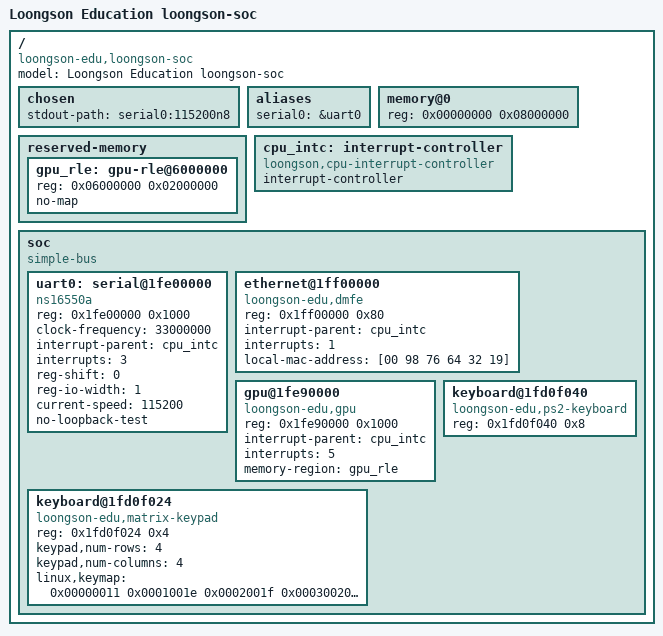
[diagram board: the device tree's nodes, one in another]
// SPDX-License-Identifier: GPL-2.0
/dts-v1/;

/ {
	model = "Loongson Education loongson-soc";
	compatible = "loongson-edu,loongson-soc";
	#address-cells = <1>;
	#size-cells = <1>;

	chosen {
		stdout-path = "serial0:115200n8";
	};

	aliases {
		serial0 = &uart0;
	};

	memory@0 {
		device_type = "memory";
		reg = <0x00000000 0x08000000>;
	};

	reserved-memory {
		#address-cells = <1>;
		#size-cells = <1>;
		ranges;

		/* Large physically-contiguous CPU<->GPU shared region for RLE data. */
		gpu_rle: gpu-rle@6000000 {
			reg = <0x06000000 0x02000000>;
			no-map;
		};
	};

	cpu_intc: interrupt-controller {
		compatible = "loongson,cpu-interrupt-controller";
		interrupt-controller;
		#interrupt-cells = <1>;
	};

	soc {
		compatible = "simple-bus";
		#address-cells = <1>;
		#size-cells = <1>;
		ranges;

		uart0: serial@1fe00000 {
			compatible = "ns16550a";
			reg = <0x1fe00000 0x1000>;
			clock-frequency = <33000000>;
			interrupt-parent = <&cpu_intc>;
			interrupts = <3>;
			reg-shift = <0>;
			reg-io-width = <1>;
			current-speed = <115200>;
			no-loopback-test;
			status = "okay";
		};

		ethernet@1ff00000 {
			compatible = "loongson-edu,dmfe";
			reg = <0x1ff00000 0x80>;
			interrupt-parent = <&cpu_intc>;
			interrupts = <1>;
			local-mac-address = [00 98 76 64 32 19];
			status = "okay";
		};

		gpu@1fe90000 {
			compatible = "loongson-edu,gpu";
			reg = <0x1fe90000 0x1000>;
			interrupt-parent = <&cpu_intc>;
			interrupts = <5>;
			memory-region = <&gpu_rle>;
			status = "okay";
		};

		keyboard@1fd0f040 {
			compatible = "loongson-edu,ps2-keyboard";
			reg = <0x1fd0f040 0x8>;
			status = "okay";
		};

		keyboard@1fd0f024 {
			compatible = "loongson-edu,matrix-keypad";
			reg = <0x1fd0f024 0x4>;
			keypad,num-rows = <4>;
			keypad,num-columns = <4>;
			/*
			 * Matrix keymap placeholder: adjust row/col to the actual board
			 * silkscreen labels before relying on it for DOOM.
			 * KEY(row, col, keycode) encoded as (row<<24)|(col<<16)|keycode.
			 */
			linux,keymap = <
				0x00000011 0x0001001e 0x0002001f 0x00030020
				0x01000067 0x0101006c 0x01020069 0x0103006a
				0x02000039 0x0201001d 0x0202002a 0x0203001c
				0x03000001 0x0301000f 0x0302000e 0x03030061>;
			status = "okay";
		};
	};
};
